# F28x7x_spi_regs register map
Vendor: Texas Instruments
Peripheral module from a debugger description file (folder C2000).
Address unit: 16 bits
Registers are 16-bit, read-write, no defined reset value unless marked. A register's access mark holds for its fields unless they carry their own. Offsets are as the file gives them; lines under a group give offsets from that group; [hi:lo] are bit positions; {n}, {i} and the like mark numbered series; 'fields as' and 'values as' point back to an identical list; <NAME> marks a mode.

## SPI_REGS
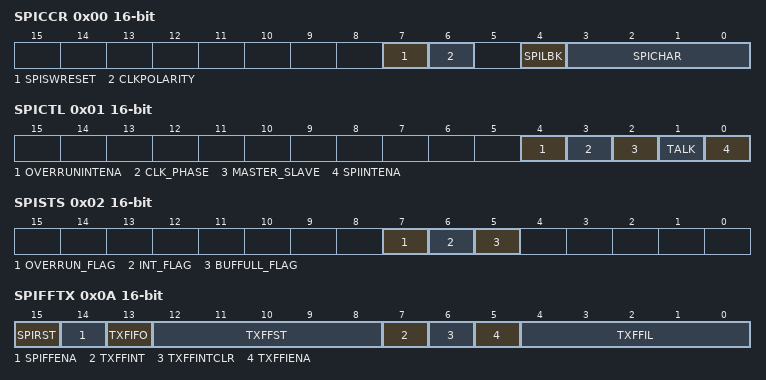
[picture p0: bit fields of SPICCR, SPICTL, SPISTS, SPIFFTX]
0x00 SPICCR access per field — SPI Configuration Control Register
  [7] SPISWRESET rw — SPI Software Reset
    0=SPI operating flags are set to the reset condition; 1=SPI is ready to transmit or receive the next character
  [6] CLKPOLARITY ro — SPI Shift Clock Polarity
    0=SPI Data is output on rising edge and input on falling edge; 1=SPI Data is output on falling edge and input on rising edge
  [4] SPILBK rw — SPI Loopback Mode Select
    0=SPI Loopback mode disabled; 1=SPI Loopback mode enabled, SIMO/SOMI lines connected internally
  [3:0] SPICHAR rw — SPI Character Length Control Bits
0x01 SPICTL — SPI Operation Control Register
  [4] OVERRUNINTENA — Overrun Interrupt Enable
    0=Disable RECEIVER OVERRUN interrupts; 1=Enable RECEIVER_OVERRUN interrupts
  [3] CLK_PHASE — SPI Clock Phase
    0=Normal SPI clocking scheme, depending on the CLOCK POLARITY bit; 1=SPICLK signal delayed by one half-cycle
  [2] MASTER_SLAVE — SPI Network Mode Control
    0=SPI is configured as a slave; 1=SPI is configured as a master
  [1] TALK — Master/Slave Transmit Enable
    0=Disables transmission:[[br]]- Slave mode operation: If not prev; 1=Enables transmission For the 4-pin option, ensure to enable the
  [0] SPIINTENA — SPI Interupt Enable
    0=Disables the interrupt; 1=Enables the interrupt
0x02 SPISTS — SPI Status Register
  [7] OVERRUN_FLAG — SPI Receiver Overrun Flag
    0=A receive overrun condition has not occurred; 1=The last received character has been overwritten and therefore
  [6] INT_FLAG — SPI Interrupt Flag
    0=No full words have been received or transmitted; 1=Indicates that the SPI has completed sending or receiving the l
  [5] BUFFULL_FLAG — SPI Transmit Buffer Full Flag
    0=Transmit buffer is not full; 1=Transmit buffer is full
0x04 SPIBRR — SPI Baud Rate Register
  [6:0] SPI_BIT_RATE — SPI Bit Rate Control
    {v}=__{v} (SPI Baud Rate = LSPCLK/{v+1}) (v=3..9); {v}=__{v+6} (SPI Baud Rate = LSPCLK/{v+1}) (v=10..19); {v}=__{v+12} (SPI Baud Rate = LSPCLK/{v+1}) (v=20..29); {v}=__{v+18} (SPI Baud Rate = LSPCLK/{v+1}) (v=30..39); {v}=__{v+24} (SPI Baud Rate = LSPCLK/{v+1}) (v=40..49); {v}=__{v+30} (SPI Baud Rate = LSPCLK/{v+1}) (v=50..59); {v}=__{v+36} (SPI Baud Rate = LSPCLK/{v+1}) (v=60..63); 64=SPI Baud Rate = LSPCLK/65; 65=SPI Baud Rate = LSPCLK/66; {v}=__{v+36} (SPI Baud Rate = LSPCLK/{v+1}) (v=66..69); {v}=__{v+42} (SPI Baud Rate = LSPCLK/{v+1}) (v=70..79); {v}=__{v+48} (SPI Baud Rate = LSPCLK/{v+1}) (v=80..89); {v}=__{v+54} (SPI Baud Rate = LSPCLK/{v+1}) (v=90..99); {v}=__{v+156} (SPI Baud Rate = LSPCLK/{v+1}) (v=100..109); {v}=__{v+162} (SPI Baud Rate = LSPCLK/{v+1}) (v=110..119); {v}=__{v+168} (SPI Baud Rate = LSPCLK/{v+1}) (v=120..127)
0x06 SPIRXEMU — SPI Emulation Buffer Register
  [15:0] ERXBn — Emulation Buffer Received Data
0x07 SPIRXBUF — SPI Serial Input Buffer Register
  [15:0] RXBn — Received Data
0x08 SPITXBUF — SPI Serial Output Buffer Register
  [15:0] TXBn — Transmit Data Buffer
0x09 SPIDAT — SPI Serial Data Register
  [15:0] SDATn — Serial Data Shift Register
0x0A SPIFFTX — SPI FIFO Transmit Register
  [15] SPIRST — SPI Reset
    0=Write 0 to reset the SPI transmit and receive channels; 1=SPI FIFO can resume transmit or receive
  [14] SPIFFENA — FIFO Enhancements Enable
    0=SPI FIFO enhancements are disabled; 1=SPI FIFO enhancements are enabled
  [13] TXFIFO — TXFIFO Reset
    0=Write 0 to reset the FIFO pointer to zero, and hold in reset; 1=Release transmit FIFO from reset
  [12:8] TXFFST — Transmit FIFO Status
    0=Transmit FIFO is empty; 1=Transmit FIFO has 1 word; 2=__2 (Transmit FIFO has 2 words.); 3=__3 (Transmit FIFO has 3 words.); 4=__4 (Transmit FIFO has 4 words, which is the maximum.)
  [7] TXFFINT — TXFIFO Interrupt Flag
    0=TXFIFO interrupt has not occurred, This is a read-only bit; 1=TXFIFO interrupt has occurred, This is a read-only bit
  [6] TXFFINTCLR — TXFIFO Interrupt Clear
    0=Write 0 has no effect on TXFIFINT flag bit, Bit reads back a ze; 1=Write 1 to clear SPIFFTX[TXFFINT] flag
  [5] TXFFIENA — TXFIFO Interrupt Enable
    0=TX FIFO interrupt based on TXFFIL match (less than or equal to); 1=TX FIFO interrupt based on TXFFIL match (less than or equal to)
  [4:0] TXFFIL — TXFIFO Interrupt Level
    0=A TX FIFO interrupt request is generated when there are no word; 1=A TX FIFO interrupt request is generated when there is 1 word o; 2=__2 (A TX FIFO interrupt request is generated when there are 2 words); 3=__3 (A TX FIFO interrupt request is generated when there are 3 words); 4=__4 (A TX FIFO interrupt request is generated when there are 4 words); 31=__49 (Reserved.)
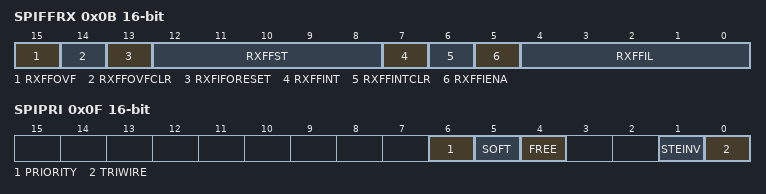
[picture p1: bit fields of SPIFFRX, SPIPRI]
0x0B SPIFFRX — SPI FIFO Receive Register
  [15] RXFFOVF — Receive FIFO Overflow Flag
    0=Receive FIFO has not overflowed. This is a read-only bit.; 1=Receive FIFO has overflowed, read-only bit
  [14] RXFFOVFCLR — Receive FIFO Overflow Clear
    0=Write 0 does not affect RXFFOVF flag bit, Bit reads back a zero; 1=Write 1 to clear SPIFFRX[RXFFOVF]
  [13] RXFIFORESET
    0=Write 0 to reset the FIFO pointer to zero, and hold in reset; 1=Re-enable receive FIFO operation
  [12:8] RXFFST — Receive FIFO Status
    0=Receive FIFO is empty; 1=Receive FIFO has 1 word; 2=__2 (Receive FIFO has 2 words.); 3=__3 (Receive FIFO has 3 words.); 4=__4 (Receive FIFO has 4 words, which is the maximum.)
  [7] RXFFINT — RXFIFO Interrupt Flag
    0=RXFIFO interrupt has not occurred. This is a read-only bit.; 1=RXFIFO interrupt has occurred. This is a read-only bit.
  [6] RXFFINTCLR — RXFIFO Interupt Clear
    0=Write 0 has no effect on RXFIFINT flag bit, Bit reads back a ze; 1=Write 1 to clear SPIFFRX[RXFFINT] flag
  [5] RXFFIENA — RXFIFO Interrupt Enable
    0=RX FIFO interrupt based on RXFFIL match (greater than or equal; 1=RX FIFO interrupt based on RXFFIL match (greater than or equal
  [4:0] RXFFIL — RXFIFO Interrupt Level
    1=A RX FIFO interrupt request is generated when there is 1 or mor; 2=__2 (A RX FIFO interrupt request is generated when there are 2 or mo); 3=__3 (A RX FIFO interrupt request is generated when there are 3 or mo); 4=__4 (A RX FIFO interrupt request is generated when there are 4 words)
0x0C SPIFFCT — SPI FIFO Control Register
  [7:0] TXDLY — FIFO Transmit Delay Bits
    0=The next word in the TX FIFO buffer is transferred to SPITXBUF; 1=The next word in the TX FIFO buffer is transferred to SPITXBUF1; 2=__2 (The next word in the TX FIFO buffer is transferred to SPITXBUF); 255=__597 (The next word in the TX FIFO buffer is transferred to SPITXBUF)
0x0F SPIPRI — SPI Priority Control Register
  [6] PRIORITY — Interrupt priority select
  [5] SOFT — Soft emulation mode
    0=Transmission stops after midway in the bit stream while TSUSPEN; 1=If the emulation suspend occurs before the start of a transmiss
  [4] FREE — Free emulation mode
    0=Emulation mode is selected by the SOFT bit; 1=Free run, continue SPI operation regardless of suspend or when
  [1] STEINV — SPISTE inversion bit
    0=SPISTEn is active low (normal); 1=SPISTE is active high (inverted)
  [0] TRIWIRE — 3-wire mode select bit
    0=Normal 4-wire SPI mode; 1=3-wire SPI mode enabled
